VERSION "1.0"

NS_ :

BS_:

BU_: PCM1 FOO

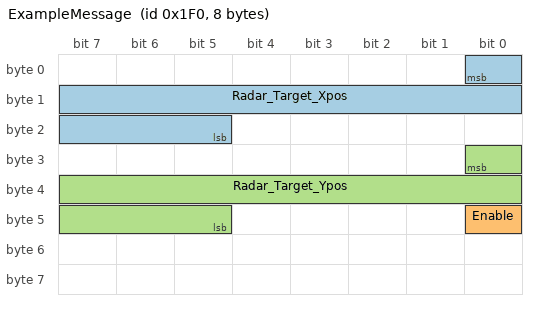
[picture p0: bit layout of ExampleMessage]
BO_ 496 ExampleMessage: 8 PCM1
 SG_ Radar_Target_Xpos : 0|12@0- (0.01,250) [0|270.47] ""  Vector__XXX
 SG_ Enable : 40|1@0+ (1,0) [0|0] "-" Vector__XXX
 SG_ Radar_Target_Ypos : 24|12@0- (0.01,250) [0|270.47] ""  Vector__XXX

CM_ BO_ 496 "Example message used as template in MotoHawk models.";

VAL_ 496 Enable 0 "Disabled" 1 "Enabled" ;
